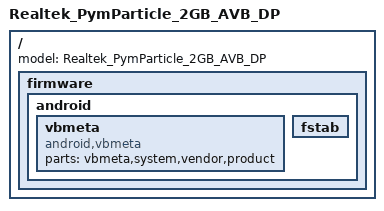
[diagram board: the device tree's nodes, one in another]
#include "rtd-1319-pymparticle-2GB.dts"
#include "rtd-13xx-avb.dtsi"

/ {
	model= "Realtek_PymParticle_2GB_AVB_DP";
	firmware {
		android {
			vbmeta {
				compatible = "android,vbmeta";
				parts = "vbmeta,system,vendor,product";
				};
			fstab {
				/delete-node/ system;
				/delete-node/ vendor;
				/delete-node/ product;
			};
		};
	};

};

